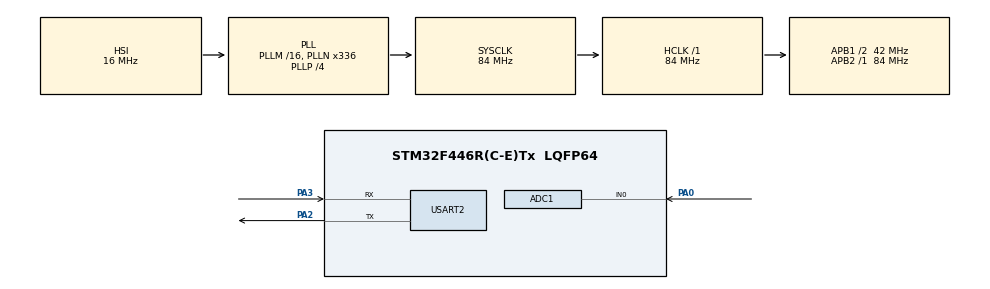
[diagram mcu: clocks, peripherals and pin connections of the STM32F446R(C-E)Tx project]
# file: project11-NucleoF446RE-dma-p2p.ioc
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ADC1.Channel-1\#ChannelRegularConversion=ADC_CHANNEL_0
ADC1.ContinuousConvMode=ENABLE
ADC1.NbrOfConversionFlag=1
ADC1.Rank-1\#ChannelRegularConversion=1
ADC1.SamplingTime-1\#ChannelRegularConversion=ADC_SAMPLETIME_3CYCLES
ADC1.master=1
Dma.Request0=USART2_TX
Dma.USART2_TX.0.Direction=DMA_MEMORY_TO_PERIPH
Dma.USART2_TX.0.FIFOMode=DMA_FIFOMODE_DISABLE
Dma.USART2_TX.0.Instance=DMA1_Stream6
Dma.USART2_TX.0.MemDataAlignment=DMA_MDATAALIGN_BYTE
Dma.USART2_TX.0.MemInc=DMA_MINC_ENABLE
Dma.USART2_TX.0.Mode=DMA_CIRCULAR
Dma.USART2_TX.0.PeriphDataAlignment=DMA_PDATAALIGN_BYTE
Dma.USART2_TX.0.PeriphInc=DMA_PINC_DISABLE
Dma.USART2_TX.0.Priority=DMA_PRIORITY_LOW
Mcu.Family=STM32F4
Mcu.Name=STM32F446R(C-E)Tx
Mcu.Package=LQFP64
NVIC.DMA1_Stream6_IRQn=true\:0\:0\:false\:false\:true\:false\:true\:true
NVIC.PriorityGroup=NVIC_PRIORITYGROUP_0
PA0-WKUP.Signal=ADCx_IN0
PA2.Mode=Asynchronous
PA2.Signal=USART2_TX
PA3.Mode=Asynchronous
PA3.Signal=USART2_RX
ProjectManager.HeapSize=0x200
ProjectManager.StackSize=0x400
ProjectManager.TargetToolchain=STM32CubeIDE
RCC.48MHZClocksFreq_Value=84000000
RCC.AHBFreq_Value=84000000
RCC.APB1CLKDivider=RCC_HCLK_DIV2
RCC.APB1Freq_Value=42000000
RCC.APB1TimFreq_Value=84000000
RCC.APB2Freq_Value=84000000
RCC.APB2TimFreq_Value=84000000
RCC.CortexFreq_Value=84000000
RCC.FLatency-AdvancedSettings=FLASH_LATENCY_2
RCC.HCLKFreq_Value=84000000
RCC.HSE_VALUE=8000000
RCC.HSI_VALUE=16000000
RCC.PLLN=336
RCC.PLLP=RCC_PLLP_DIV4
RCC.SYSCLKFreq_VALUE=84000000
RCC.SYSCLKSource=RCC_SYSCLKSOURCE_PLLCLK
RCC.USBFreq_Value=168000000
RCC.VCOOutputFreq_Value=336000000
SH.ADCx_IN0.0=ADC1_IN0,IN0
USART2.VirtualMode=VM_ASYNC
board=NUCLEO-F446RE

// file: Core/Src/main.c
/* USER CODE BEGIN Header */
/**
  ******************************************************************************
  * @file           : main.c
  * @brief          : Main program body
  ******************************************************************************
  * @attention
  *
  * Copyright (c) 2025 STMicroelectronics.
  * All rights reserved.
  *
  * This software is licensed under terms that can be found in the LICENSE file
  * in the root directory of this software component.
  * If no LICENSE file comes with this software, it is provided AS-IS.
  *
  ******************************************************************************
  */
/* USER CODE END Header */
#include "main.h"

/* USER CODE BEGIN Includes */

#define ADC_BUF_LEN 32

uint16_t adc_buf[ADC_BUF_LEN];   // buffer filled by ADC DMA
char msg[64];                    // UART transmit buffer
/* USER CODE END Includes */

ADC_HandleTypeDef hadc1;

UART_HandleTypeDef huart2;
DMA_HandleTypeDef hdma_usart2_tx;

void SystemClock_Config(void);
static void MX_GPIO_Init(void);
static void MX_DMA_Init(void);
static void MX_ADC1_Init(void);
static void MX_USART2_UART_Init(void);
/* USER CODE BEGIN PFP */
ADC_HandleTypeDef hadc1;
UART_HandleTypeDef huart2;
/* USER CODE END PFP */

/* USER CODE BEGIN 0 */
// ADC Half-Transfer Callback
void HAL_ADC_ConvHalfCpltCallback(ADC_HandleTypeDef* hadc)
{
  if (hadc->Instance == ADC1)
  {
    // Example: send the first sample of the half-buffer
    sprintf(msg, "ADC: %u\r\n", adc_buf[0]);
    HAL_UART_Transmit_DMA(&huart2, (uint8_t*)msg, strlen(msg));
  }
}

// ADC Transfer-Complete Callback
void HAL_ADC_ConvCpltCallback(ADC_HandleTypeDef* hadc)
{
  if (hadc->Instance == ADC1)
  {
    // Example: send the first sample of the second half
    sprintf(msg, "ADC: %u\r\n", adc_buf[ADC_BUF_LEN/2]);
    HAL_UART_Transmit_DMA(&huart2, (uint8_t*)msg, strlen(msg));
  }
}
/* USER CODE END 0 */

int main(void)
{

  /* MCU Configuration--------------------------------------------------------*/

  /* Reset of all peripherals, Initializes the Flash interface and the Systick. */
  HAL_Init();

  /* Configure the system clock */
  SystemClock_Config();

  /* Initialize all configured peripherals */
  MX_GPIO_Init();
  MX_DMA_Init();
  MX_ADC1_Init();
  MX_USART2_UART_Init();
  /* USER CODE BEGIN 2 */
  HAL_ADC_Start_DMA(&hadc1, (uint32_t*)adc_buf, ADC_BUF_LEN);

  /* USER CODE END 2 */

  /* Infinite loop */
  while (1)
  {

  }
}

void SystemClock_Config(void)
{
  RCC_OscInitTypeDef RCC_OscInitStruct = {0};
  RCC_ClkInitTypeDef RCC_ClkInitStruct = {0};

  /** Configure the main internal regulator output voltage
  */
  __HAL_RCC_PWR_CLK_ENABLE();
  __HAL_PWR_VOLTAGESCALING_CONFIG(PWR_REGULATOR_VOLTAGE_SCALE3);

  /** Initializes the RCC Oscillators according to the specified parameters
  * in the RCC_OscInitTypeDef structure.
  */
  RCC_OscInitStruct.OscillatorType = RCC_OSCILLATORTYPE_HSI;
  RCC_OscInitStruct.HSIState = RCC_HSI_ON;
  RCC_OscInitStruct.HSICalibrationValue = RCC_HSICALIBRATION_DEFAULT;
  RCC_OscInitStruct.PLL.PLLState = RCC_PLL_ON;
  RCC_OscInitStruct.PLL.PLLSource = RCC_PLLSOURCE_HSI;
  RCC_OscInitStruct.PLL.PLLM = 16;
  RCC_OscInitStruct.PLL.PLLN = 336;
  RCC_OscInitStruct.PLL.PLLP = RCC_PLLP_DIV4;
  RCC_OscInitStruct.PLL.PLLQ = 2;
  RCC_OscInitStruct.PLL.PLLR = 2;
  if (HAL_RCC_OscConfig(&RCC_OscInitStruct) != HAL_OK)
  {
    Error_Handler();
  }

  /** Initializes the CPU, AHB and APB buses clocks
  */
  RCC_ClkInitStruct.ClockType = RCC_CLOCKTYPE_HCLK|RCC_CLOCKTYPE_SYSCLK
                              |RCC_CLOCKTYPE_PCLK1|RCC_CLOCKTYPE_PCLK2;
  RCC_ClkInitStruct.SYSCLKSource = RCC_SYSCLKSOURCE_PLLCLK;
  RCC_ClkInitStruct.AHBCLKDivider = RCC_SYSCLK_DIV1;
  RCC_ClkInitStruct.APB1CLKDivider = RCC_HCLK_DIV2;
  RCC_ClkInitStruct.APB2CLKDivider = RCC_HCLK_DIV1;

  if (HAL_RCC_ClockConfig(&RCC_ClkInitStruct, FLASH_LATENCY_2) != HAL_OK)
  {
    Error_Handler();
  }
}

static void MX_ADC1_Init(void)
{

  ADC_ChannelConfTypeDef sConfig = {0};

  /** Configure the global features of the ADC (Clock, Resolution, Data Alignment and number of conversion)
  */
  hadc1.Instance = ADC1;
  hadc1.Init.ClockPrescaler = ADC_CLOCK_SYNC_PCLK_DIV4;
  hadc1.Init.Resolution = ADC_RESOLUTION_12B;
  hadc1.Init.ScanConvMode = DISABLE;
  hadc1.Init.ContinuousConvMode = ENABLE;
  hadc1.Init.DiscontinuousConvMode = DISABLE;
  hadc1.Init.ExternalTrigConvEdge = ADC_EXTERNALTRIGCONVEDGE_NONE;
  hadc1.Init.ExternalTrigConv = ADC_SOFTWARE_START;
  hadc1.Init.DataAlign = ADC_DATAALIGN_RIGHT;
  hadc1.Init.NbrOfConversion = 1;
  hadc1.Init.DMAContinuousRequests = DISABLE;
  hadc1.Init.EOCSelection = ADC_EOC_SINGLE_CONV;
  if (HAL_ADC_Init(&hadc1) != HAL_OK)
  {
    Error_Handler();
  }

  /** Configure for the selected ADC regular channel its corresponding rank in the sequencer and its sample time.
  */
  sConfig.Channel = ADC_CHANNEL_0;
  sConfig.Rank = 1;
  sConfig.SamplingTime = ADC_SAMPLETIME_3CYCLES;
  if (HAL_ADC_ConfigChannel(&hadc1, &sConfig) != HAL_OK)
  {
    Error_Handler();
  }

}

static void MX_USART2_UART_Init(void)
{

  huart2.Instance = USART2;
  huart2.Init.BaudRate = 115200;
  huart2.Init.WordLength = UART_WORDLENGTH_8B;
  huart2.Init.StopBits = UART_STOPBITS_1;
  huart2.Init.Parity = UART_PARITY_NONE;
  huart2.Init.Mode = UART_MODE_TX_RX;
  huart2.Init.HwFlowCtl = UART_HWCONTROL_NONE;
  huart2.Init.OverSampling = UART_OVERSAMPLING_16;
  if (HAL_UART_Init(&huart2) != HAL_OK)
  {
    Error_Handler();
  }

}

static void MX_DMA_Init(void)
{

  /* DMA controller clock enable */
  __HAL_RCC_DMA1_CLK_ENABLE();

  /* DMA interrupt init */
  /* DMA1_Stream6_IRQn interrupt configuration */
  HAL_NVIC_SetPriority(DMA1_Stream6_IRQn, 0, 0);
  HAL_NVIC_EnableIRQ(DMA1_Stream6_IRQn);

}

static void MX_GPIO_Init(void)
{

  /* GPIO Ports Clock Enable */
  __HAL_RCC_GPIOA_CLK_ENABLE();

}

void Error_Handler(void)
{
  __disable_irq();
  while (1)
  {
  }
}
